# STM32MP25_CM33 register map
File version: 1.3
CPU: CM33 r0p1, little endian, MPU, FPU, vendor SysTick, 8 interrupt priority bits
Registers are 32-bit, read-write, reset 0x0 unless marked. A register's access mark holds for its fields unless they carry their own. Offsets are from the block's base; [hi:lo] are bit positions; {n}, {i} and the like mark numbered series; 'fields as' and 'values as' point back to an identical list.

## RCC (part 3 of 3) — RCC register block
Base 0x44200000
Same registers: RCC_S 0x54200000
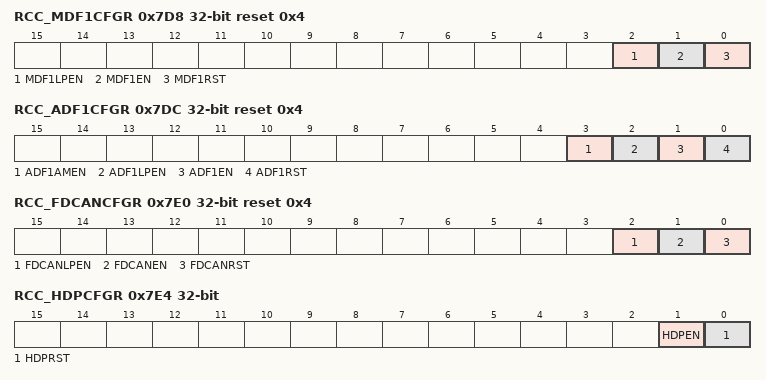
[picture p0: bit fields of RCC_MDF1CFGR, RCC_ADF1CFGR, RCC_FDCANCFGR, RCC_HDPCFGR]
0x7D8 RCC_MDF1CFGR reset 0x4 — RCC MDF1 configuration register
  [2] MDF1LPEN — MDF1 clock enable during CSleep
    0=Writing 0 disables peripheral clocks in CSleep; 1=Writing 1 enables peripheral clocks in CSleep
  [1] MDF1EN — MDF1 clock enable
    0=Writing 0 disables peripheral clocks; 1=Writing 1 enables peripheral clocks
  [0] MDF1RST — MDF1 reset
    0=Writing 0 releases MDF1 reset; 1=Writing 1 asserts MDF1 reset
0x7DC RCC_ADF1CFGR reset 0x4 — RCC ADF1 configuration register
  [3] ADF1AMEN — ADF1 autonomous clock mode enable
    0=Writing 0 disables autonomous clock mode; 1=Writing 1 enables autonomous clock mode
  [2] ADF1LPEN — ADF1 clock enable during CSleep
    values as RCC_MDF1CFGR.MDF1LPEN
  [1] ADF1EN — ADF1 clock enable
    values as RCC_MDF1CFGR.MDF1EN
  [0] ADF1RST — ADF1 reset
    0=Writing 0 releases ADF1 reset; 1=Writing 1 asserts ADF1 reset
0x7E0 RCC_FDCANCFGR reset 0x4 — RCC FDCAN configuration register
  [2] FDCANLPEN — FDCAN clock enable during CSleep
    values as RCC_MDF1CFGR.MDF1LPEN
  [1] FDCANEN — FDCAN clock enable
    values as RCC_MDF1CFGR.MDF1EN
  [0] FDCANRST — FDCAN reset
    0=Writing 0 releases FDCAN reset; 1=Writing 1 asserts FDCAN reset
0x7E4 RCC_HDPCFGR — RCC HDP configuration register
  [1] HDPEN — HDP clock enable
    values as RCC_MDF1CFGR.MDF1EN
  [0] HDPRST — HDP reset
    0=Writing 0 releases HDP reset; 1=Writing 1 asserts HDP reset
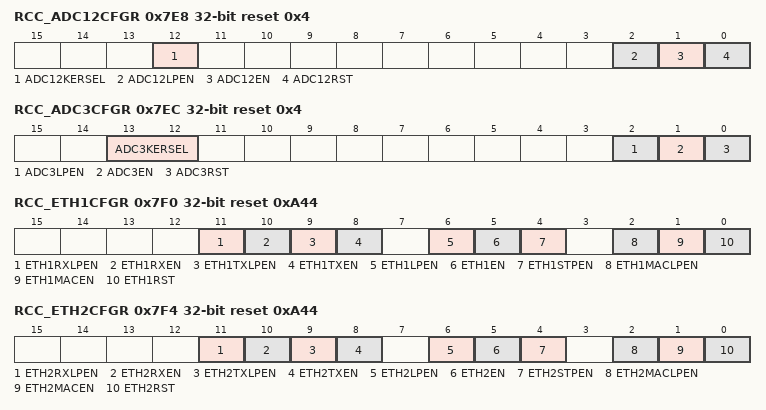
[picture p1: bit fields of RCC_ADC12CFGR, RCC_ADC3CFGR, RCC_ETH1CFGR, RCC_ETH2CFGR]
0x7E8 RCC_ADC12CFGR reset 0x4 — RCC ADC12 configuration register
  [12] ADC12KERSEL — ADC12 kernel clock source selection
    0=Kernel clock source is ck_ker_adc12; 1=Kernel clock source is ck_icn_ls_mcu
  [2] ADC12LPEN — ADC12 clock enable during CSleep
    values as RCC_MDF1CFGR.MDF1LPEN
  [1] ADC12EN — ADC12 clock enable
    values as RCC_MDF1CFGR.MDF1EN
  [0] ADC12RST — ADC12 reset
    0=Writing 0 releases ADC12 reset; 1=Writing 1 asserts ADC12 reset
0x7EC RCC_ADC3CFGR reset 0x4 — RCC ADC3 configuration register
  [13:12] ADC3KERSEL — ADC3 kernel clock source select
    0=Kernel source clock is ck_ker_adc3; 1=Kernel source clock is ck_icn_ls_mcu; 2=Kernel source clock is ck_ker_adc12
  [2] ADC3LPEN — ADC3 clock enable during CSleep
    values as RCC_MDF1CFGR.MDF1LPEN
  [1] ADC3EN — ADC3 clock enable
    values as RCC_MDF1CFGR.MDF1EN
  [0] ADC3RST — ADC3 reset
    0=Writing 0 releases ADC3 reset; 1=Writing 1 asserts ADC3 reset
0x7F0 RCC_ETH1CFGR reset 0xA44 — RCC Ethernet 1 configuration register
  [11] ETH1RXLPEN — Ethernet 1 reception clock enable during CSleep
    0=Writing 0 disables reception clock in CSleep; 1=Writing 1 enables reception clock in CSleep
  [10] ETH1RXEN — Ethernet 1 reception clock enable
    0=Writing 0 disables reception clock; 1=Writing 1 enables reception clock
  [9] ETH1TXLPEN — Ethernet 1 transmission clock enable during CSleep
    0=Writing 0 disables transmission clock in CSleep; 1=Writing 1 enables transmission clock in CSleep
  [8] ETH1TXEN — Ethernet 1 transmission clock enable
    0=Writing 0 disables transmission clock; 1=Writing 1 enables transmission clock
  [6] ETH1LPEN — Ethernet 1 kernel clock enable during CSleep
    0=Writing 0 disables kernel clocks in CSleep; 1=Writing 1 enables kernel clocks in CSleep
  [5] ETH1EN — Ethernet 1 kernel clock enable
    0=Writing 0 disables kernel clocks; 1=Writing 1 enables kernel clocks
  [4] ETH1STPEN — Ethernet 1 kernel clocks enable during CStop
    0=Writing 0 disables ETH1 TX and RX kernel clocks in CStop; 1=Writing 1 enables ETH1 TX and RX kernel clocks in CStop
  [2] ETH1MACLPEN — Ethernet 1 bus clock enable during CSleep
    0=Writing 0 disables bus clocks in CSleep; 1=Writing 1 enables bus clocks in CSleep
  [1] ETH1MACEN — Ethernet 1 bus clock enable
    0=Writing 0 disables bus clocks; 1=Writing 1 enables bus clocks
  [0] ETH1RST — Ethernet 1 reset
    0=Writing 0 releases ETH1 reset; 1=Writing 1 asserts ETH1 reset
0x7F4 RCC_ETH2CFGR reset 0xA44 — RCC Ethernet 2 configuration register
  [11] ETH2RXLPEN — Ethernet 2 reception clock enable during CSleep
    values as RCC_ETH1CFGR.ETH1RXLPEN
  [10] ETH2RXEN — Ethernet 2 reception clock enable
    values as RCC_ETH1CFGR.ETH1RXEN
  [9] ETH2TXLPEN — Ethernet 2 transmission clock enable during CSleep mode
    values as RCC_ETH1CFGR.ETH1TXLPEN
  [8] ETH2TXEN — Ethernet 2 transmission clock enable
    values as RCC_ETH1CFGR.ETH1TXEN
  [6] ETH2LPEN — Ethernet 2 kernel clocks enable during CSleep
    values as RCC_ETH1CFGR.ETH1LPEN
  [5] ETH2EN — Ethernet 2 kernel clocks enable
    values as RCC_ETH1CFGR.ETH1EN
  [4] ETH2STPEN — Ethernet 2 kernel clocks enable during CStop
    0=Writing 0 disables ETH2 TX and RX kernel clocks in CStop; 1=Writing 1 enables ETH2 TX and RX kernel clocks in CStop
  [2] ETH2MACLPEN — Ethernet 2 bus clock enable during CSleep
    values as RCC_ETH1CFGR.ETH1MACLPEN
  [1] ETH2MACEN — Ethernet 2 bus clock enable
    values as RCC_ETH1CFGR.ETH1MACEN
  [0] ETH2RST — Ethernet 2 reset
    0=Writing 0 releases ETH2 reset; 1=Writing 1 asserts ETH2 reset
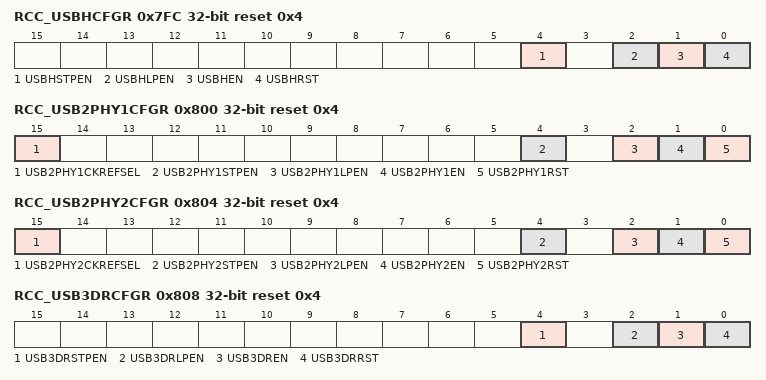
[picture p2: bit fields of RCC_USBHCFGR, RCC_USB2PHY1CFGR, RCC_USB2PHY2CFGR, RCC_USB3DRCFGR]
0x7FC RCC_USBHCFGR reset 0x4 — RCC USBH configuration register
  [4] USBHSTPEN — USBH clock enable during CStop
    0=Writing 0 disables peripheral clocks in CStop; 1=Writing 1 enables peripheral clocks in CStop
  [2] USBHLPEN — USBH clock enable during CSleep
    values as RCC_MDF1CFGR.MDF1LPEN
  [1] USBHEN — USBH peripheral clock enable
    values as RCC_MDF1CFGR.MDF1EN
  [0] USBHRST — USBH reset
    0=Writing 0 releases USBH reset; 1=Writing 1 asserts USBH reset
0x800 RCC_USB2PHY1CFGR reset 0x4 — RCC USB2PHY1 configuration register
  [15] USB2PHY1CKREFSEL — USB2PHY1 reference clock selection
    0=USB2PHY1 reference clock is channel 57 (ck_ker_usb2phy1) of the flexclkgen; 1=USB2PHY1 reference clock is the HSE oscillator (hse_ker_ck)
  [4] USB2PHY1STPEN — USB2PHY1 reference clock enable during CStop
    0=Writing 0 disables reference clock in CStop; 1=Writing 1 enables reference clock in CStop
  [2] USB2PHY1LPEN — USB2PHY1 clock enable during CSleep
    values as RCC_MDF1CFGR.MDF1LPEN
  [1] USB2PHY1EN — USB2PHY1 clock enable
    values as RCC_MDF1CFGR.MDF1EN
  [0] USB2PHY1RST — USB2PHY1 reset
    0=Writing 0 releases USB2PHY1 reset; 1=Writing 1 asserts USB2PHY1 reset
0x804 RCC_USB2PHY2CFGR reset 0x4 — RCC USB2PHY2 configuration register
  [15] USB2PHY2CKREFSEL — USB2PHY2 reference clock select
    0=USB2PHY2 reference clock is channel 58 (ck_ker_usb2phy2) of the flexclkgen; 1=USB2PHY2 reference clock is the HSE oscillator (hse_ker_ck)
  [4] USB2PHY2STPEN — USB2PHY2 reference clock enable during CStop
    values as RCC_USB2PHY1CFGR.USB2PHY1STPEN
  [2] USB2PHY2LPEN — USB2PHY2 clock enable during CSleep
    values as RCC_MDF1CFGR.MDF1LPEN
  [1] USB2PHY2EN — USB2PHY2 clock enable
    values as RCC_MDF1CFGR.MDF1EN
  [0] USB2PHY2RST — USB2PHY2 reset
    0=Writing 0 releases USB2PHY2 reset; 1=Writing 1 asserts USB2PHY2 reset
0x808 RCC_USB3DRCFGR reset 0x4 — RCC USB3DR configuration register
  [4] USB3DRSTPEN — USB3DR clock enable during CStop
    values as RCC_USB2PHY1CFGR.USB2PHY1STPEN
  [2] USB3DRLPEN — USB3DR clock enable during CSleep
    values as RCC_MDF1CFGR.MDF1LPEN
  [1] USB3DREN — USB3DR peripheral clocks enable
    values as RCC_MDF1CFGR.MDF1EN
  [0] USB3DRRST — USB3DR reset
    0=Writing 0 releases USB3DR reset; 1=Writing 1 asserts USB3DR reset
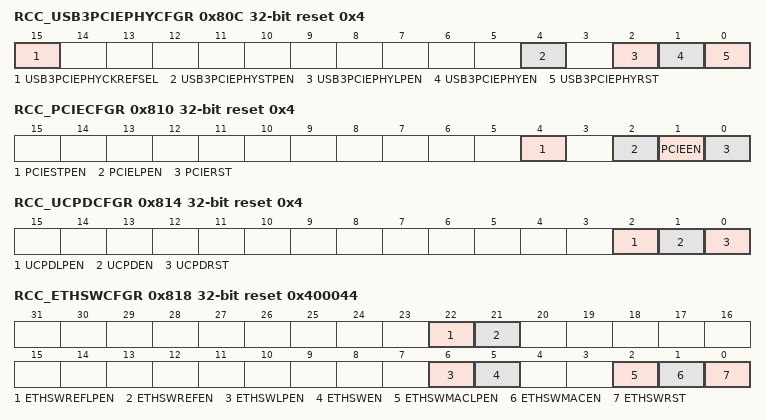
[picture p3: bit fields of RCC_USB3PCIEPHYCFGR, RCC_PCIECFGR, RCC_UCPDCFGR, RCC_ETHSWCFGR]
0x80C RCC_USB3PCIEPHYCFGR reset 0x4 — RCC USB3PCIEPHY configuration register
  [15] USB3PCIEPHYCKREFSEL — USB3PCIEPHY reference clock selection
    0=USB3PCIEPHY reference clock is channel 34 (ck_ker_usb3pciephy) of the flexclkgen (default after reset); 1=USB3PCIEPHY reference clock is the HSE oscillator (hse_ker_ck)
  [4] USB3PCIEPHYSTPEN — USB3PCIEPHY reference clock enable during CStop
    values as RCC_USB2PHY1CFGR.USB2PHY1STPEN
  [2] USB3PCIEPHYLPEN — USB3PCIEPHY clock enable during CSleep
    values as RCC_MDF1CFGR.MDF1LPEN
  [1] USB3PCIEPHYEN — USB3PCIEPHY clock enable
    values as RCC_MDF1CFGR.MDF1EN
  [0] USB3PCIEPHYRST — USB3PCIEPHY reset
    0=Writing 0 releases USB3PCIEPHY reset; 1=Writing 1 asserts USB3PCIEPHY reset
0x810 RCC_PCIECFGR reset 0x4 — RCC PCIE configuration register
  [4] PCIESTPEN — PCIE clock enable during CStop
    values as RCC_USBHCFGR.USBHSTPEN
  [2] PCIELPEN — PCIE clock enable during CSleep
    values as RCC_MDF1CFGR.MDF1LPEN
  [1] PCIEEN — PCIE clock enable
    values as RCC_MDF1CFGR.MDF1EN
  [0] PCIERST — PCIE reset
    0=Writing 0 releases PCIE reset; 1=Writing 1 asserts PCIE reset
0x814 RCC_UCPDCFGR reset 0x4 — RCC UCPD configuration register
  [2] UCPDLPEN — UCPD clock enable during CSleep
    values as RCC_MDF1CFGR.MDF1LPEN
  [1] UCPDEN — UCPD clock enable
    values as RCC_MDF1CFGR.MDF1EN
  [0] UCPDRST — UCPD reset
    0=Writing 0 releases UCPD reset; 1=Writing 1 asserts UCPD reset
0x818 RCC_ETHSWCFGR reset 0x400044 — RCC Ethernet switch configuration register
  [22] ETHSWREFLPEN — ETHSW ck_ker_ethswref kernel clock enable during CSleep
    0=Writing 0 disables ck_ker_ethswref in CSleep; 1=Writing 1 enables ck_ker_ethswref in CSleep
  [21] ETHSWREFEN — ETHSW ck_ker_ethswref kernel clock enable
    0=Writing 0 disables ck_ker_ethswref; 1=Writing 1 enables ck_ker_ethswref
  [6] ETHSWLPEN — ETHSW ck_ker_ethsw kernel clock enable during CSleep
    0=Writing 0 disables ck_ker_ethsw in CSleep; 1=Writing 1 enables ck_ker_ethsw in CSleep
  [5] ETHSWEN — ETHSW ck_ker_ethsw kernel clock enable
    0=Writing 0 disables ck_ker_ethsw; 1=Writing 1 enables ck_ker_ethsw
  [2] ETHSWMACLPEN — ETHSW clock enable during CSleep
    values as RCC_MDF1CFGR.MDF1LPEN
  [1] ETHSWMACEN — ETHSW clock enable
    values as RCC_MDF1CFGR.MDF1EN
  [0] ETHSWRST — ETHSW reset
    0=Writing 0 releases ETHSW reset; 1=Writing 1 asserts ETHSW reset
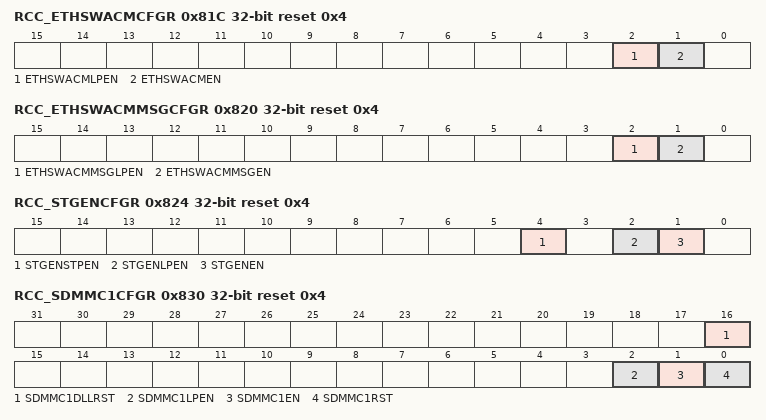
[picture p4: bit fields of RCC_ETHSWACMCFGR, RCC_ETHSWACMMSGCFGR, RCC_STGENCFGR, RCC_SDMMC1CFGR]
0x81C RCC_ETHSWACMCFGR reset 0x4 — RCC Ethernet switch ACM configuration register
  [2] ETHSWACMLPEN — ETHSW_ACM clock enable during CSleep
    values as RCC_MDF1CFGR.MDF1LPEN
  [1] ETHSWACMEN — ETHSW_ACM clock enable
    values as RCC_MDF1CFGR.MDF1EN
0x820 RCC_ETHSWACMMSGCFGR reset 0x4 — RCC Ethernet switch ACM message configuration register
  [2] ETHSWACMMSGLPEN — ETHSW_ACM message buffer clock enable during CSleep
    values as RCC_MDF1CFGR.MDF1LPEN
  [1] ETHSWACMMSGEN — ETHSW_ACM message buffer clock enable
    values as RCC_MDF1CFGR.MDF1EN
0x824 RCC_STGENCFGR reset 0x4 — RCC STGEN configuration register
  [4] STGENSTPEN — STGENRW and STGENRO kernel clock enable during CStop
    0=Writing 0 disables kernel clocks in CStop; 1=Writing 1 enables kernel clocks in CStop
  [2] STGENLPEN — STGENRW and STGENRO clock enable during CSleep
    values as RCC_MDF1CFGR.MDF1LPEN
  [1] STGENEN — STGENRW and STGENRO clock enable
    values as RCC_MDF1CFGR.MDF1EN
0x830 RCC_SDMMC1CFGR reset 0x4 — RCC SDMMC1 configuration register
  [16] SDMMC1DLLRST — SDMMC1 DLL reset
    0=Writing 0 releases DLL reset; 1=Writing 1 asserts DLL reset
  [2] SDMMC1LPEN — SDMMC1 clock enable during CSleep
    values as RCC_MDF1CFGR.MDF1LPEN
  [1] SDMMC1EN — SDMMC1 clock enable
    values as RCC_MDF1CFGR.MDF1EN
  [0] SDMMC1RST — SDMMC1 reset
    0=Writing 0 releases SDMMC1 reset; 1=Writing 1 asserts SDMMC1 reset
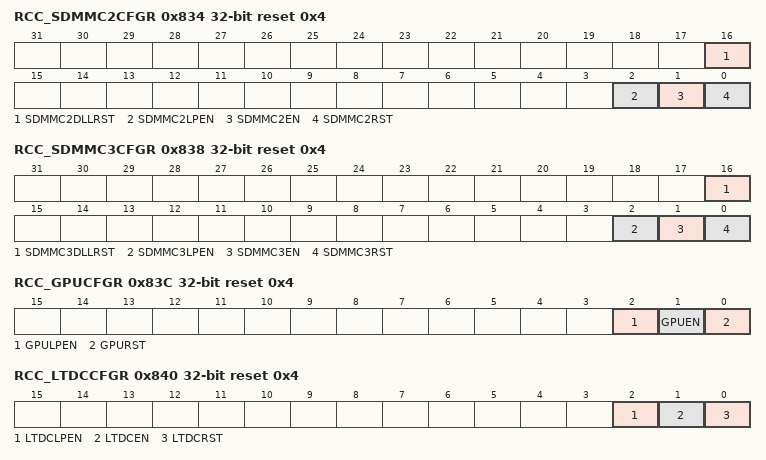
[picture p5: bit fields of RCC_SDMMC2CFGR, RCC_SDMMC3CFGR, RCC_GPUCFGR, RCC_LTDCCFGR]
0x834 RCC_SDMMC2CFGR reset 0x4 — RCC SDMMC2 configuration register
  [16] SDMMC2DLLRST — SDMMC2 DLL reset
    values as RCC_SDMMC1CFGR.SDMMC1DLLRST
  [2] SDMMC2LPEN — SDMMC2 clock enable during CSleep
    values as RCC_MDF1CFGR.MDF1LPEN
  [1] SDMMC2EN — SDMMC2 clock enable
    values as RCC_MDF1CFGR.MDF1EN
  [0] SDMMC2RST — SDMMC2 reset
    0=Writing 0 releases SDMMC2 reset; 1=Writing 1 asserts SDMMC2 reset
0x838 RCC_SDMMC3CFGR reset 0x4 — RCC SDMMC3 configuration register
  [16] SDMMC3DLLRST — SDMMC3 DLL reset
    values as RCC_SDMMC1CFGR.SDMMC1DLLRST
  [2] SDMMC3LPEN — SDMMC3 clock enable during CSleep
    values as RCC_MDF1CFGR.MDF1LPEN
  [1] SDMMC3EN — SDMMC3 clock enable
    values as RCC_MDF1CFGR.MDF1EN
  [0] SDMMC3RST — SDMMC3 block reset
    0=Writing 0 releases SDMMC3 reset; 1=Writing 1 asserts SDMMC3 reset
0x83C RCC_GPUCFGR reset 0x4 — RCC GPU configuration register
  [2] GPULPEN — GPU clock enable during CSleep
    values as RCC_MDF1CFGR.MDF1LPEN
  [1] GPUEN — GPU clock enable
    values as RCC_MDF1CFGR.MDF1EN
  [0] GPURST — GPU reset
    0=Writing 0 has no effect; 1=Writing 1 asserts GPU reset
0x840 RCC_LTDCCFGR reset 0x4 — RCC LTDC configuration register
  [2] LTDCLPEN — LTDC clock enable during CSleep
    values as RCC_MDF1CFGR.MDF1LPEN
  [1] LTDCEN — LTDC peripheral clock enable
    values as RCC_MDF1CFGR.MDF1EN
  [0] LTDCRST — LTDC reset
    0=Writing 0 releases LTDC reset; 1=Writing 1 asserts LTDC reset
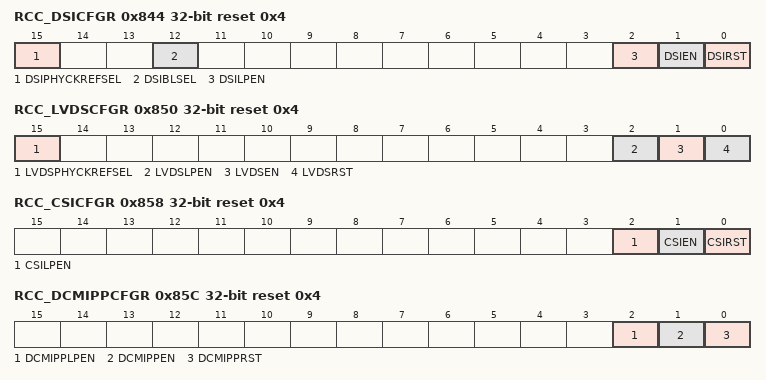
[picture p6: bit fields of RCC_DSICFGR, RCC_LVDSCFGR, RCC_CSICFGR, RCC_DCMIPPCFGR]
0x844 RCC_DSICFGR reset 0x4 — RCC DSI configuration register
  [15] DSIPHYCKREFSEL — DSIPHY reference clock selection
    0=DSIPHY reference clock is channel 28 (ck_ker_dsiphy) of the flexclkgen; 1=DSIPHY reference clock is the HSE oscillator (hse_ck)
  [12] DSIBLSEL — DSI byte lane clock source selection
    0=DSIPHY clock is selected as DSI byte lane clock source (default after reset); 1=Clock channel 27 (ck_ker_ltdc) of flexclkgen is selected as DSI byte lane clock source
  [2] DSILPEN — DSI clock enable during CSleep
    values as RCC_MDF1CFGR.MDF1LPEN
  [1] DSIEN — DSI clock enable
    values as RCC_MDF1CFGR.MDF1EN
  [0] DSIRST — DSI reset
    values as RCC_LTDCCFGR.LTDCRST
0x850 RCC_LVDSCFGR reset 0x4 — RCC LVDS configuration register
  [15] LVDSPHYCKREFSEL — LVDSPHY reference clock select
    0=LVDSPHY reference clock is channel 32 (ck_ker_lvdsphy) of the flexclkgen; 1=LVDSPHY reference clock is the HSE oscillator (hse_ker_ck)
  [2] LVDSLPEN — LVDSPHY clock enable during CSleep
    values as RCC_MDF1CFGR.MDF1LPEN
  [1] LVDSEN — LVDSPHY clock enable
    values as RCC_MDF1CFGR.MDF1EN
  [0] LVDSRST — LVDS reset
    0=Writing 0 releases LVDS reset; 1=Writing 1 asserts LVDS reset
0x858 RCC_CSICFGR reset 0x4 — RCC CSI configuration register
  [2] CSILPEN — CSI clock enable during CSleep
    values as RCC_MDF1CFGR.MDF1LPEN
  [1] CSIEN — CSI clock enable
    values as RCC_MDF1CFGR.MDF1EN
  [0] CSIRST — CSI reset
    0=Writing 0 releases CSI reset; 1=Writing 1 asserts CSI reset
0x85C RCC_DCMIPPCFGR reset 0x4 — RCC DCMIPP configuration register
  [2] DCMIPPLPEN — DCMIPP clock enable during CSleep
    values as RCC_MDF1CFGR.MDF1LPEN
  [1] DCMIPPEN — DCMIPP clock enable
    values as RCC_MDF1CFGR.MDF1EN
  [0] DCMIPPRST — DCMIPP reset
    0=Writing 0 releases DCMIPP reset; 1=Writing 1 asserts DCMIPP reset
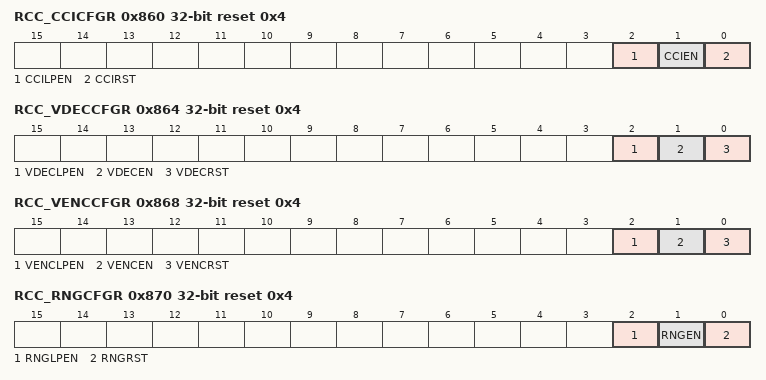
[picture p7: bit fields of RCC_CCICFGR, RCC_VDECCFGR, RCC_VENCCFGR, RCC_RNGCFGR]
0x860 RCC_CCICFGR reset 0x4 — RCC CCI configuration register
  [2] CCILPEN — CCI clock enable during CSleep
    values as RCC_MDF1CFGR.MDF1LPEN
  [1] CCIEN — CCI clock enable
    values as RCC_MDF1CFGR.MDF1EN
  [0] CCIRST — CCI reset
    0=Writing 0 releases CCI reset; 1=Writing 1 asserts CCI reset
0x864 RCC_VDECCFGR reset 0x4 — RCC VDEC configuration register
  [2] VDECLPEN — VDEC clock enable during CSleep
    values as RCC_MDF1CFGR.MDF1LPEN
  [1] VDECEN — VDEC clock enable
    values as RCC_MDF1CFGR.MDF1EN
  [0] VDECRST — VDEC reset
    0=Writing 0 releases VDEC reset; 1=Writing 1 asserts VDEC reset
0x868 RCC_VENCCFGR reset 0x4 — RCC VENC configuration register
  [2] VENCLPEN — VENC clock enable during CSleep
    values as RCC_MDF1CFGR.MDF1LPEN
  [1] VENCEN — VENC clock enable
    values as RCC_MDF1CFGR.MDF1EN
  [0] VENCRST — VENC reset
    0=Writing 0 releases VENC reset; 1=Writing 1 asserts VENC reset
0x870 RCC_RNGCFGR reset 0x4 — RCC RNG configuration register
  [2] RNGLPEN — RNG clock enable during CSleep
    values as RCC_MDF1CFGR.MDF1LPEN
  [1] RNGEN — RNG clock enable
    values as RCC_MDF1CFGR.MDF1EN
  [0] RNGRST — RNG reset
    0=Writing 0 releases RNG reset; 1=Writing 1 asserts RNG reset
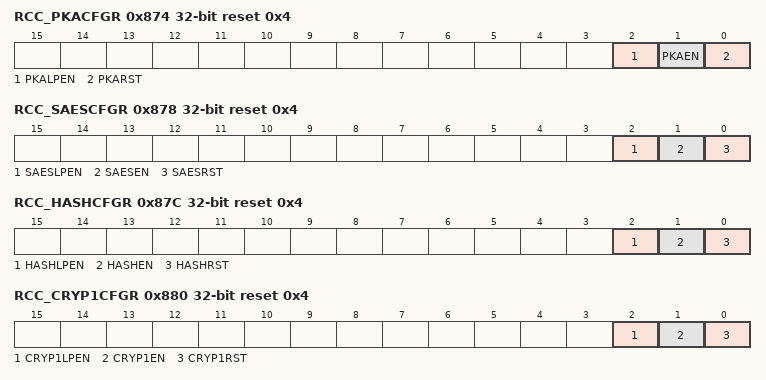
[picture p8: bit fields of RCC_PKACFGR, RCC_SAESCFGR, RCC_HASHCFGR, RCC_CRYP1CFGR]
0x874 RCC_PKACFGR reset 0x4 — RCC PKA configuration register
  [2] PKALPEN — PKA clock enable during CSleep
    values as RCC_MDF1CFGR.MDF1LPEN
  [1] PKAEN — PKA clock enable
    values as RCC_MDF1CFGR.MDF1EN
  [0] PKARST — PKA reset
    0=Writing 0 releases PKA reset; 1=Writing 1 asserts PKA reset
0x878 RCC_SAESCFGR reset 0x4 — RCC SAES configuration register
  [2] SAESLPEN — SAES clock enable during CSleep
    values as RCC_MDF1CFGR.MDF1LPEN
  [1] SAESEN — SAES clock enable
    values as RCC_MDF1CFGR.MDF1EN
  [0] SAESRST — SAES reset
    0=Writing 0 releases SAES reset; 1=Writing 1 asserts SAES reset
0x87C RCC_HASHCFGR reset 0x4 — RCC HASH configuration register
  [2] HASHLPEN — HASH clock enable during CSleep
    values as RCC_MDF1CFGR.MDF1LPEN
  [1] HASHEN — HASH clock enable
    values as RCC_MDF1CFGR.MDF1EN
  [0] HASHRST — HASH reset
    0=Writing 0 releases HASH reset; 1=Writing 1 asserts HASH reset
0x880 RCC_CRYP1CFGR reset 0x4 — RCC CRYP1 configuration register
  [2] CRYP1LPEN — CRYP1 clock enable during CSleep
    values as RCC_MDF1CFGR.MDF1LPEN
  [1] CRYP1EN — CRYP1 clock enable
    values as RCC_MDF1CFGR.MDF1EN
  [0] CRYP1RST — CRYP1 reset
    0=Writing 0 releases CRYP1 reset; 1=Writing 1 asserts CRYP1 reset
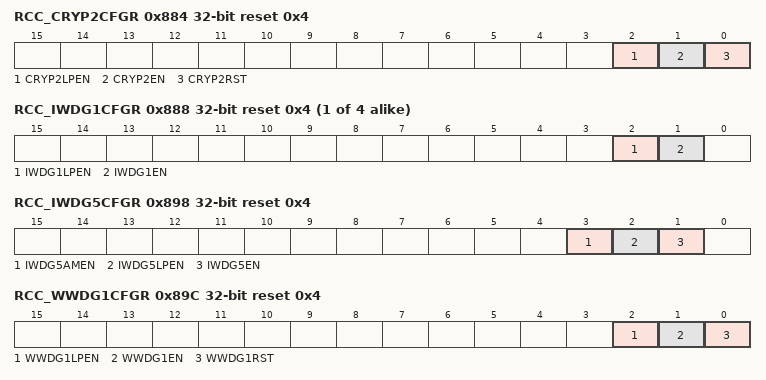
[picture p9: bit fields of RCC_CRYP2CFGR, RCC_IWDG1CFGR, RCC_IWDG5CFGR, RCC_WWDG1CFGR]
0x884 RCC_CRYP2CFGR reset 0x4 — RCC CRYP2 configuration register
  [2] CRYP2LPEN — CRYP2 clock enable during CSleep
    values as RCC_MDF1CFGR.MDF1LPEN
  [1] CRYP2EN — CRYP2 clock enable
    values as RCC_MDF1CFGR.MDF1EN
  [0] CRYP2RST — CRYP2 reset
    0=Writing 0 releases CRYP2 reset; 1=Writing 1 asserts CRYP2 reset
{0x884+4i} RCC_IWDG{i}CFGR reset 0x4 (i=1..4) — RCC IWDG{i} configuration register
  [2] IWDG{i}LPEN — IWDG{i} bus clock enable during CSleep
    0=Writing 0 disables APB clock in CSleep; 1=Writing 1 enables APB clock in CSleep
  [1] IWDG{i}EN — IWDG{i} bus clock enable
    0=Writing 0 disables APB clock; 1=Writing 1 enables APB clock
0x898 RCC_IWDG5CFGR reset 0x4 — RCC IWDG5 configuration register
  [3] IWDG5AMEN — IWDG5 autonomous clock mode enable
    values as RCC_ADF1CFGR.ADF1AMEN
  [2] IWDG5LPEN — IWDG5 bus clock enable during CSleep
    values as RCC_IWDG1CFGR.IWDG{i}LPEN
  [1] IWDG5EN — IWDG5 bus clock enable
    values as RCC_IWDG1CFGR.IWDG{i}EN
0x89C RCC_WWDG1CFGR reset 0x4 — RCC WWDG1 configuration register
  [2] WWDG1LPEN — WWDG1 bus clock enable during CSleep
    values as RCC_IWDG1CFGR.IWDG{i}LPEN
  [1] WWDG1EN — WWDG1 bus clock enable
    values as RCC_IWDG1CFGR.IWDG{i}EN
  [0] WWDG1RST — WWDG1 reset
    0=Writing 0 releases WWDG1 reset; 1=Writing 1 asserts WWDG1 reset
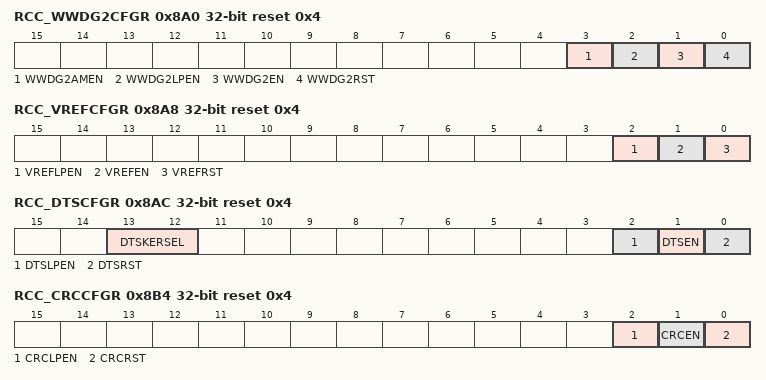
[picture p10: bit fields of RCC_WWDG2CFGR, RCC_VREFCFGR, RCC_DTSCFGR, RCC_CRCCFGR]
0x8A0 RCC_WWDG2CFGR reset 0x4 — RCC WWDG2 configuration register
  [3] WWDG2AMEN — WWDG2 autonomous clock mode enable
    values as RCC_ADF1CFGR.ADF1AMEN
  [2] WWDG2LPEN — WWDG2 bus clock enable during CSleep
    values as RCC_IWDG1CFGR.IWDG{i}LPEN
  [1] WWDG2EN — WWDG2 bus clock enable
    values as RCC_IWDG1CFGR.IWDG{i}EN
  [0] WWDG2RST — WWDG2 block reset
    0=Writing 0 releases WWDG2 reset; 1=Writing 1 asserts WWDG2 reset
0x8A8 RCC_VREFCFGR reset 0x4 — RCC VREF configuration register
  [2] VREFLPEN — VREF clock enable during CSleep
    values as RCC_MDF1CFGR.MDF1LPEN
  [1] VREFEN — VREF clock enable
    values as RCC_MDF1CFGR.MDF1EN
  [0] VREFRST — VREF reset
    0=Writing 0 releases VREF reset; 1=Writing 1 asserts VREF reset
0x8AC RCC_DTSCFGR reset 0x4 — RCC DTS configuration register
  [13:12] DTSKERSEL — DTS kernel clock selection
    0=hsi_ker_ck selected; 1=hse_ker_ck selected; 2=msi_ker_ck selected
  [2] DTSLPEN — DTS clock enable during CSleep
    values as RCC_MDF1CFGR.MDF1LPEN
  [1] DTSEN — DTS clock enable
    values as RCC_MDF1CFGR.MDF1EN
  [0] DTSRST — DTS reset
    0=Writing 0 releases DTS reset; 1=Writing 1 asserts DTS reset
0x8B4 RCC_CRCCFGR reset 0x4 — RCC CRC configuration register
  [2] CRCLPEN — CRC clock enable during CSleep
    values as RCC_MDF1CFGR.MDF1LPEN
  [1] CRCEN — CRC clock enable
    values as RCC_MDF1CFGR.MDF1EN
  [0] CRCRST — CRC reset
    0=Writing 0 releases CRC reset; 1=Writing 1 asserts CRC reset
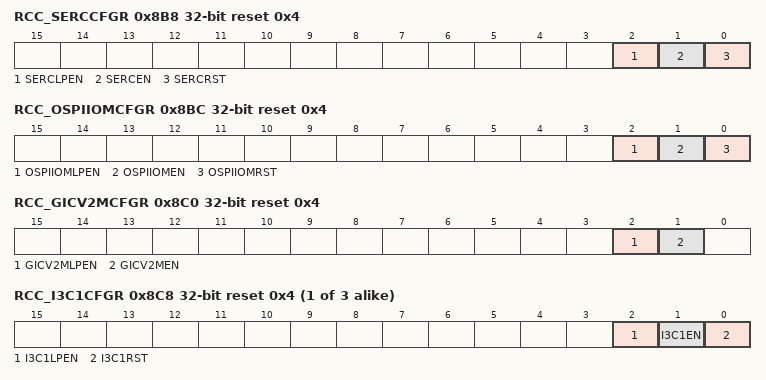
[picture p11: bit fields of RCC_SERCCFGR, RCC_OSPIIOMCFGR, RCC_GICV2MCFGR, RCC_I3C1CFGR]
0x8B8 RCC_SERCCFGR reset 0x4 — RCC SERC configuration register
  [2] SERCLPEN — SERC clock enable during CSleep
    values as RCC_MDF1CFGR.MDF1LPEN
  [1] SERCEN — SERC clocks enable
    values as RCC_MDF1CFGR.MDF1EN
  [0] SERCRST — SERC reset
    0=Writing 0 releases SERC reset; 1=Writing 1 asserts SERC reset
0x8BC RCC_OSPIIOMCFGR reset 0x4 — RCC OCTOSPI I/O manager configuration register
  [2] OSPIIOMLPEN — OCTOSPIM clock enable during CSleep
    values as RCC_MDF1CFGR.MDF1LPEN
  [1] OSPIIOMEN — OCTOSPIM clock enable
    values as RCC_MDF1CFGR.MDF1EN
  [0] OSPIIOMRST — OCTOSPIM reset
    0=Writing 0 releases OCTOSPIM reset; 1=Writing 1 asserts OCTOSPIM reset
0x8C0 RCC_GICV2MCFGR reset 0x4 — RCC GICV2M configuration register
  [2] GICV2MLPEN — GICV2M clock enable during CSleep
    values as RCC_MDF1CFGR.MDF1LPEN
  [1] GICV2MEN — GICV2M clock enable
    values as RCC_MDF1CFGR.MDF1EN
{0x8C4+4i} RCC_I3C{i}CFGR reset 0x4 (i=1..3) — RCC I3C{i} configuration register
  [2] I3C{i}LPEN — I3C{i} clock enable during CSleep
    values as RCC_MDF1CFGR.MDF1LPEN
  [1] I3C{i}EN — I3C{i} clock enable
    values as RCC_MDF1CFGR.MDF1EN
  [0] I3C{i}RST — I3C{i} reset
    0=Writing 0 releases I3C{i} reset; 1=Writing 1 asserts I3C{i} reset
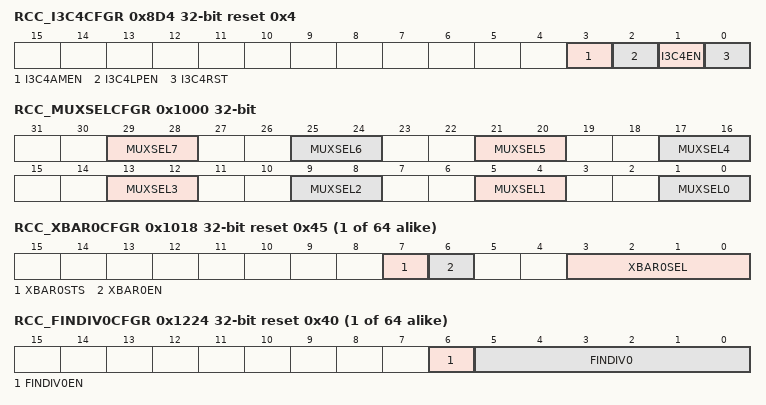
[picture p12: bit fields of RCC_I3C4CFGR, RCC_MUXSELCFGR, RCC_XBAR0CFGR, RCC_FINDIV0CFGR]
0x8D4 RCC_I3C4CFGR reset 0x4 — RCC I3C4 configuration register
  [3] I3C4AMEN — I3C4 autonomous clock mode enable
    values as RCC_ADF1CFGR.ADF1AMEN
  [2] I3C4LPEN — I3C4 clock enable during CSleep
    values as RCC_MDF1CFGR.MDF1LPEN
  [1] I3C4EN — I3C4 clock enable
    values as RCC_MDF1CFGR.MDF1EN
  [0] I3C4RST — I3C4 reset
    0=Writing 0 releases I3C4 reset; 1=Writing 1 asserts I3C4 reset
0x1000 RCC_MUXSELCFGR — RCC MUXSEL configuration register
  [all] fields
    0=hsi_ck; 1=hse_ck; 2=msi_ck
  [29:28] MUXSEL7 — PLL3 reference clock selection (ck_pll3_ref)
  [25:24] MUXSEL6 — PLL2 reference clock selection (ck_pll2_ref)
  [21:20] MUXSEL5 — PLL1 reference clock selection (ck_pll1_ref)
  [4n+1:4n] MUXSEL{n} (n=0..4) — PLL{n+4} reference clock selection
{0x1018+4i} RCC_XBAR{i}CFGR reset 0x45 (i=0..63) — RCC cross bar {i} configuration register
  [7] XBAR{i}STS ro — Cross bar channel x output status
    0=Channel x is aligned to given settings; 1=Indicates change ongoing
  [6] XBAR{i}EN — Cross bar channel x clock output enable
    0=Channel x output disabled; 1=Channel x output enabled
  [3:0] XBAR{i}SEL — Cross bar channel x input clock selection
    {v}=PLL{v+4} FOUTPOSTDIV clock selected (v=0..4); 5=hsi_ck selected; 6=hse_ck selected; 7=msi_ck selected; 8=hsi_ker_ck selected; 9=hse_ker_ck selected; 10=msi_ker_ck selected; 11=spdif_ck_symb selected; 12=i2s_ck selected (AUDIOCLK pin); 13=lsi_ck selected; 14=lse_ck selected
{0x1118+4i} RCC_PREDIV{i}CFGR (i=0..63) — RCC pre divider {i} configuration register
  [9:0] PREDIV{i} — Predivider channel x divider ratio
    0=div1; 1=div2; 3=div4; 0x3FF=div1024
0x1218 RCC_PREDIVSR1 ro — RCC pre divider status register 1
  [31:0] PREDIVSTS — Predivider channel[31:0] output status
    0=Channel is aligned with divide ratio change; 1=Indicates that the divider is in the process of changing
0x121C RCC_PREDIVSR2 ro — RCC pre divider status register 2
  [31:0] PREDIVSTS — Predivider channel[63:32] output status
    values as RCC_PREDIVSR1.PREDIVSTS
{0x1224+4i} RCC_FINDIV{i}CFGR reset 0x40 (i=0..63) — RCC final divider {i} configuration register
  [6] FINDIV{i}EN — Final divider channel x output enable
    0=Channel x output disabled; 1=Channel x output enabled
  [5:0] FINDIV{i} — Channel x divider ratio
0x1324 RCC_FINDIVSR1 ro — RCC final divider status register 1
  [31:0] FINDIVSTS — Final divider channel[31:0] output status
    values as RCC_PREDIVSR1.PREDIVSTS
0x1328 RCC_FINDIVSR2 ro — RCC final divider status register 2
  [31:0] FINDIVSTS — Final divider channel[63:32] output status
    values as RCC_PREDIVSR1.PREDIVSTS
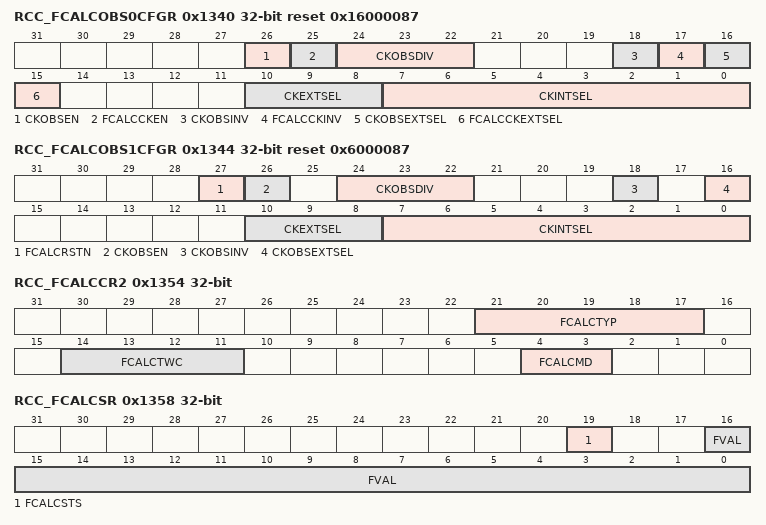
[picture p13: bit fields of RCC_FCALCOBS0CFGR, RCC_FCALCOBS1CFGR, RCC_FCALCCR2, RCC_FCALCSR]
0x1340 RCC_FCALCOBS0CFGR reset 0x16000087 — RCC clock frequency calculator and observation 0 clock configuration register
  [26] CKOBSEN — Observation clock 0 output enable
    0=Observation clock 0 output disabled; 1=Observation clock 0 output enabled (default after reset)
  [25] FCALCCKEN — Clock frequency calculator input clock enable
    0=Input clock disabled; 1=Input clock enabled (default after reset)
  [24:22] CKOBSDIV — Observation clock 0 divide ratio
    0=div1 (default after reset); 1=div2; 2=div4; 3=div8; 4=div16; 5=div32; 6=div64; 7=div128
  [18] CKOBSINV — Observation clock 0 inverter
    0=Observation clock 0 not inverted (default after reset); 1=Observation clock 0 inverted
  [17] FCALCCKINV — Clock frequency calculator input clock inverter
    0=Input clock not inverted (default after reset); 1=Input clock inverted
  [16] CKOBSEXTSEL — External clock source for observation clock 0
    0=Internal clock selected for observation clock 0 (default after reset); 1=External clock selected for observation clock 0
  [15] FCALCCKEXTSEL — External clock source for clock frequency calculator input clock
    0=Internal clock selected for the clock frequency calculator input clock (default after reset); 1=External clock selected for the clock frequency calculator input clock
  [10:8] CKEXTSEL — External clock selector for clock frequency calculator and
    0=pll1 clock divided by 42; 1=pll2 clock divided by 4; 2=pll3 clock divided by 2; 3=usb2phy1 PLL clock; 4=usb2phy2 PLL clock; 5=usb3pciephy PLL clock; 6=lvdsphy PLL clock; 7=dsiphy PLL clock
  [7:0] CKINTSEL — Internal clock selector for clock frequency calculator and observation clock 0
    0=hsi_ck; 1=hse_ck; 2=msi_ck; {v}=PLL{v-1} reference input clock (v=5..9); 10=PLL1 reference input clock; 11=PLL2 reference input clock; 12=PLL3 reference input clock; {v}=PLL{v-60} output clock (v=64..68); 128=hsi_ker_ck; 129=hse_ker_ck; 130=msi_ker_ck; 131=spdif_symb_ck; 132=i2s_ck (AUDIOCLK pin); 133=lsi_ck; 134=lse_ck; 135=ck_xbar_fsm (default after reset); 136=ck_icn_p_rcc; 192=findiv[0]; 193=findiv[1]; 255=findiv[63]
0x1344 RCC_FCALCOBS1CFGR reset 0x6000087 — RCC clock frequency calculator and observation 1 clock configuration register
  [27] FCALCRSTN — Clock frequency calculator reset
    0=Clock frequency calculator reset module asserted (default after reset); 1=Clock frequency calculator reset module released
  [26] CKOBSEN — Observation clock 1 output enable
    0=Observation clock 1 output disabled; 1=Observation clock 1 output enabled (default after reset)
  [24:22] CKOBSDIV — Observation clock 1 divide ratio
    values as RCC_FCALCOBS0CFGR.CKOBSDIV
  [18] CKOBSINV — Observation clock 1 inverter
    0=Observation clock 1 not inverted (default after reset); 1=Observation clock 1 inverted
  [16] CKOBSEXTSEL — External clock source for the observation clock 1
    0=Internal clock selected for observation clock 1(default after reset); 1=External clock selected for observation clock 1
  [10:8] CKEXTSEL — External clock for observation clock 1
    values as RCC_FCALCOBS0CFGR.CKEXTSEL
  [7:0] CKINTSEL — Internal clock selector for observation clock 1
    values as RCC_FCALCOBS0CFGR.CKINTSEL
0x1348 RCC_FCALCREFCFGR reset 0x4000 — RCC clock frequency calculator reference clock configuration register
  [2:0] FCALCREFCKSEL — Reference clock selection used by clock frequency calculator
    {v}=PLL{v+4} reference input clock (v=0..4)
0x134C RCC_FCALCCR1 — RCC clock frequency calculator control register 1
  [0] FCALCRUN — Clock frequency calculator run
    0=Clock frequency calculator off (default after reset); 1=Clock frequency calculator on
0x1354 RCC_FCALCCR2 — RCC clock frequency calculator control register 2
  [21:17] FCALCTYP — Clock frequency calculation type selection
    12=Frequency value type
  [14:11] FCALCTWC — Time window code for clock frequency calculation
    0=63 cycles; 1=3 cycles; 2=7 cycles; 3=15 cycles; 4=31 cycles; 5=63 cycles; 6=127 cycles; 7=255 cycles; 8=511 cycles; 9=1023 cycles; 10=2047 cycles; 11=4095 cycles; 12=8191 cycles; 13=16383 cycles; 14=32767 cycles; 15=65535 cycles
  [4:3] FCALCMD — Clock frequency calculation method
    3=Application method
0x1358 RCC_FCALCSR ro — RCC clock frequency calculator status register
  [19] FCALCSTS — Clock frequency calculation status
  [16:0] FVAL — Clock frequency calculation value
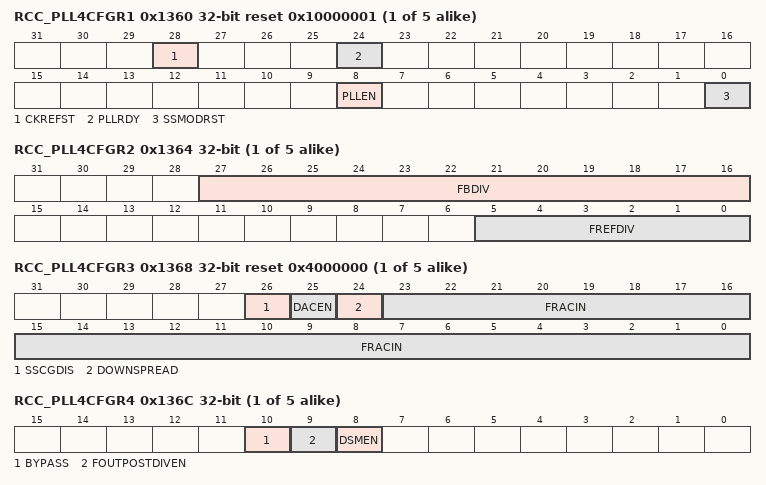
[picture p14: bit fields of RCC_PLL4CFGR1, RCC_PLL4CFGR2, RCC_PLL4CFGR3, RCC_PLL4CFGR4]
{0x12C0+0x28*i} RCC_PLL{i}CFGR1 reset 0x10000001 (i=4..8) — RCC PLL{i} configuration register 1
  [28] CKREFST — PLLy reference clock state
    0=Reading 0 means that PLLy reference clock does not run; 1=Reading 1 means that PLLy reference clock is running
  [24] PLLRDY ro — PLLy clock ready flag
    0=PLLy unlocked (default after reset); 1=PLLy locked
  [8] PLLEN — PLLy enable
    0=PLLy off (default after reset); 1=PLLy on
  [0] SSMODRST — PLLy spread-spectrum modulator reset
    0=PLLy spread-spectrum modulator reset module released; 1=PLLy spread-spectrum modulator reset module asserted (default after reset)
{0x12C4+0x28*i} RCC_PLL{i}CFGR2 (i=4..8) — RCC PLL{i} configuration register 2
  [27:16] FBDIV — PLLy VCO multiplication factor
  [5:0] FREFDIV — PLLy reference input clock divide frequency ratio
    0=Not applicable; 1=FREF divided by 1 (min value); 2=FREF divided by 2; 3=FREF divided by 3; {v}=FREF divided by {v} (v=60..63)
{0x12C8+0x28*i} RCC_PLL{i}CFGR3 reset 0x4000000 (i=4..8) — RCC PLL{i} configuration register 3
  [26] SSCGDIS — PLLy spread-spectrum modulator disable
    0=PLLy spread-spectrum modulator enabled; 1=PLLy spread-spectrum modulator disabled (default after reset)
  [25] DACEN — PLLy noise canceling DAC enable in fractional mode.
    0=DAC not active (default after reset); 1=DAC active
  [24] DOWNSPREAD — PLLy VCO frequency modulation mode
    0=Center-spread modulation selected (default after reset); 1=Down-spread modulation selected
  [23:0] FRACIN — Fractional part of PLLy VCO multiplication factor
{0x12CC+0x28*i} RCC_PLL{i}CFGR4 (i=4..8) — RCC PLL{i} configuration register 4
  [10] BYPASS — PLLy FOUTPOSTDIV bypass
    0=FOUTPOSTDIV driven by POSTDIV2; 1=FOUTPOSTDIV driven by FREF
  [9] FOUTPOSTDIVEN — PLLy output and post dividers enable
    0=FOUTPOSTDIV output, POSTDIV1, and POSTDIV2 are powered down; 1=FOUTPOSTDIV output, POSTDIV1, and POSTDIV2 dividers are active
  [8] DSMEN — PLLy delta-sigma modulator enable
    0=DSM powered down; 1=DSM active
{0x12D0+0x28*i} RCC_PLL{i}CFGR5 (i=4..8) — RCC PLL{i} configuration register 5
  [20:16] SPREAD — Modulation depth adjustment for PLLy
  [3:0] DIVVAL — Modulation frequency adjustment for PLLy
{0x12D8+0x28*i} RCC_PLL{i}CFGR6 (i=4..8) — RCC PLL{i} configuration register 6
  [2:0] POSTDIV1 — PLLy VCO frequency divide level 1
    0=Not applicable; 1=FOUTVCO divided by 1 (minimum value); 6=FOUTVCO divided by 6; 7=FOUTVCO divided by 7
{0x12DC+0x28*i} RCC_PLL{i}CFGR7 (i=4..8) — RCC PLL{i} configuration register 7
  [2:0] POSTDIV2 — PLLy VCO frequency divide level 2
    0=Not applicable; 1=FOUTVCO/POSTDIV1 divided by 1 (minimum value); 6=FOUTVCO/POSTDIV1 divided by 6; 7=FOUTVCO/POSTDIV1 divided by 7
0xFFF4 RCC_VERR ro reset 0x11 — RCC version register
  [7:4] MAJREV — Major RCC revision
  [3:0] MINREV — Minor RCC revision
0xFFF8 RCC_IDR ro reset 0x3 — RCC identifier register
  [31:0] ID — RCC identifier
0xFFFC RCC_SIDR ro reset 0xA3C5DD40 — RCC size identification register
  [31:0] SID — RCC decoding space (64 Kbytes)
